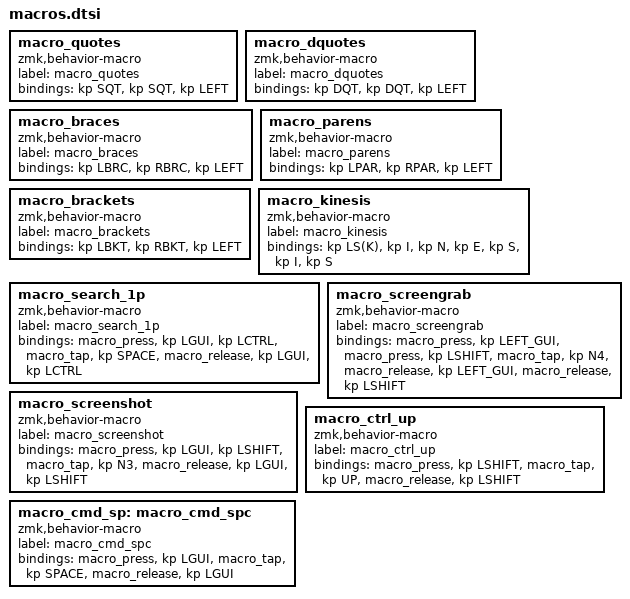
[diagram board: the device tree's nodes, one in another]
macro_quotes: macro_quotes{
compatible = "zmk,behavior-macro";
label = "macro_quotes";
#binding-cells = <0>;
bindings = <&kp SQT>, <&kp SQT>, <&kp LEFT>;
};
macro_dquotes: macro_dquotes{
compatible = "zmk,behavior-macro";
label = "macro_dquotes";
#binding-cells = <0>;
bindings = <&kp DQT>, <&kp DQT>, <&kp LEFT>;
};
macro_braces: macro_braces{
compatible = "zmk,behavior-macro";
label = "macro_braces";
#binding-cells = <0>;
bindings = <&kp LBRC>, <&kp RBRC>, <&kp LEFT>;
};
macro_parens: macro_parens{
compatible = "zmk,behavior-macro";
label = "macro_parens";
#binding-cells = <0>;
bindings = <&kp LPAR>, <&kp RPAR>, <&kp LEFT>;
};
macro_brackets: macro_brackets{
compatible = "zmk,behavior-macro";
label = "macro_brackets";
#binding-cells = <0>;
bindings = <&kp LBKT>, <&kp RBKT>, <&kp LEFT>;
};
macro_kinesis: macro_kinesis{
compatible = "zmk,behavior-macro";
label = "macro_kinesis";
#binding-cells = <0>;
bindings = <&kp LS(K)>, <&kp I>, <&kp N>, <&kp E>, <&kp S>, <&kp I>, <&kp S>;
};

macro_search_1p: macro_search_1p{
compatible = "zmk,behavior-macro";
label = "macro_search_1p";
#binding-cells = <0>;
bindings = <&macro_press &kp LGUI &kp LCTRL> , <&macro_tap &kp SPACE> , <&macro_release &kp LGUI &kp LCTRL>; 
};

macro_screengrab: macro_screengrab{
compatible = "zmk,behavior-macro";
label = "macro_screengrab";
#binding-cells = <0>;
bindings = <&macro_press &kp LEFT_GUI>, <&macro_press &kp LSHIFT>, <&macro_tap &kp N4>, <&macro_release &kp LEFT_GUI>, <&macro_release &kp LSHIFT>;
};

macro_screenshot: macro_screenshot{
compatible = "zmk,behavior-macro";
label = "macro_screenshot";
#binding-cells = <0>;
bindings = <&macro_press &kp LGUI &kp LSHIFT> , <&macro_tap &kp N3> , <&macro_release &kp LGUI &kp LSHIFT>;
};

macro_ctrl_up: macro_ctrl_up{
compatible = "zmk,behavior-macro";
label = "macro_ctrl_up";
#binding-cells = <0>;
bindings = <&macro_press &kp LSHIFT> , <&macro_tap &kp UP> , <&macro_release &kp LSHIFT>;
};
macro_cmd_sp: macro_cmd_spc{
compatible = "zmk,behavior-macro";
label = "macro_cmd_spc";
#binding-cells = <0>;
bindings = <&macro_press &kp LGUI> , <&macro_tap &kp SPACE> , <&macro_release &kp LGUI>;
};

